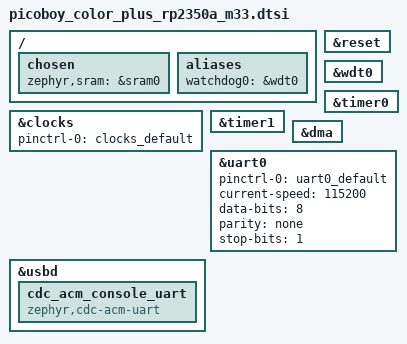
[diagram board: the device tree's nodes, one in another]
/*
 * Copyright (c) 2023-2025 TiaC Systems
 * SPDX-License-Identifier: Apache-2.0
 */

#include <mem.h>
#include <freq.h>
#include <raspberrypi/rpi_pico/rp2350a.dtsi>
#include <raspberrypi/rpi_pico/m33.dtsi>
#include <zephyr/dt-bindings/regulator/rpi_pico.h>

#include "pbcp-pinctrl.dtsi"

#define __FLASH_MBR_NODE image_def
#define __FLASH_MBR_SIZE 0x100

#define __FLASH_CTRL_NODE qmi

/ {
	chosen {
		zephyr,sram = &sram0;
	};

	aliases {
		watchdog0 = &wdt0;
	};
};

&clocks {
	pinctrl-0 = <&clocks_default>;
	pinctrl-names = "default";
};

&reset {
	status = "okay";
};

&wdt0 {
	status = "okay";
};

&timer0 {
	status = "okay";
};

&timer1 {
	status = "okay";
};

&dma {
	status = "okay";
};

&uart0 {
	status = "okay";
	pinctrl-0 = <&uart0_default>;
	pinctrl-names = "default";
	current-speed = <115200>;
	data-bits = <8>;
	parity = "none";
	stop-bits = "1";
};

zephyr_udc0: &usbd {
	status = "okay";

	cdc_acm_console_uart: cdc_acm_console_uart {
		compatible = "zephyr,cdc-acm-uart";
	};
};
